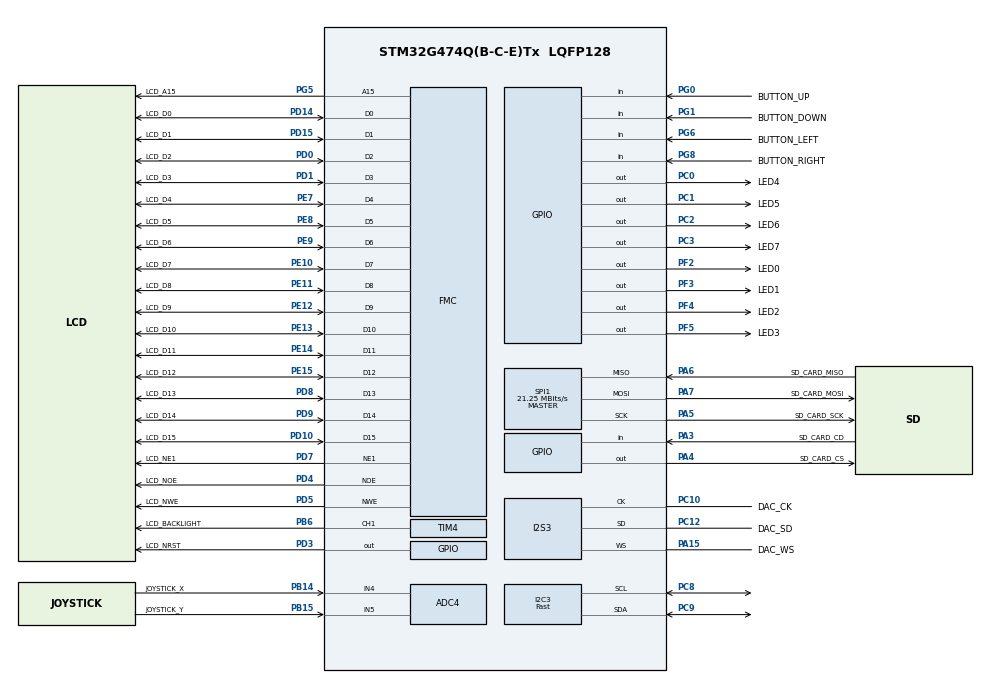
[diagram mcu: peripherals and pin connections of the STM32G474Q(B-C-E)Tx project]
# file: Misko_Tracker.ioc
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ADC4.Channel-0\#ChannelRegularConversion=ADC_CHANNEL_4
ADC4.Channel-1\#ChannelRegularConversion=ADC_CHANNEL_5
ADC4.DMAContinuousRequests=ENABLE
ADC4.ExternalTrigConv=ADC_EXTERNALTRIG_T3_TRGO
ADC4.NbrOfConversion=2
ADC4.NbrOfConversionFlag=1
ADC4.OffsetNumber-0\#ChannelRegularConversion=ADC_OFFSET_NONE
ADC4.OffsetNumber-1\#ChannelRegularConversion=ADC_OFFSET_NONE
ADC4.Rank-0\#ChannelRegularConversion=1
ADC4.Rank-1\#ChannelRegularConversion=2
ADC4.SamplingTime-0\#ChannelRegularConversion=ADC_SAMPLETIME_640CYCLES_5
ADC4.SamplingTime-1\#ChannelRegularConversion=ADC_SAMPLETIME_640CYCLES_5
Dma.ADC4.0.Direction=DMA_PERIPH_TO_MEMORY
Dma.ADC4.0.EventEnable=DISABLE
Dma.ADC4.0.Instance=DMA1_Channel2
Dma.ADC4.0.MemDataAlignment=DMA_MDATAALIGN_HALFWORD
Dma.ADC4.0.MemInc=DMA_MINC_ENABLE
Dma.ADC4.0.Mode=DMA_CIRCULAR
Dma.ADC4.0.PeriphDataAlignment=DMA_PDATAALIGN_HALFWORD
Dma.ADC4.0.PeriphInc=DMA_PINC_DISABLE
Dma.ADC4.0.Polarity=HAL_DMAMUX_REQ_GEN_RISING
Dma.ADC4.0.Priority=DMA_PRIORITY_LOW
Dma.ADC4.0.RequestNumber=1
Dma.ADC4.0.SignalID=NONE
Dma.ADC4.0.SyncEnable=DISABLE
Dma.ADC4.0.SyncPolarity=HAL_DMAMUX_SYNC_NO_EVENT
Dma.ADC4.0.SyncRequestNumber=1
Dma.ADC4.0.SyncSignalID=NONE
Dma.MEMTOMEM.1.Direction=DMA_MEMORY_TO_MEMORY
Dma.MEMTOMEM.1.EventEnable=DISABLE
Dma.MEMTOMEM.1.Instance=DMA1_Channel1
Dma.MEMTOMEM.1.MemDataAlignment=DMA_MDATAALIGN_HALFWORD
Dma.MEMTOMEM.1.MemInc=DMA_MINC_DISABLE
Dma.MEMTOMEM.1.Mode=DMA_NORMAL
Dma.MEMTOMEM.1.PeriphDataAlignment=DMA_PDATAALIGN_HALFWORD
Dma.MEMTOMEM.1.PeriphInc=DMA_PINC_ENABLE
Dma.MEMTOMEM.1.Polarity=HAL_DMAMUX_REQ_GEN_RISING
Dma.MEMTOMEM.1.Priority=DMA_PRIORITY_MEDIUM
Dma.MEMTOMEM.1.RequestNumber=1
Dma.MEMTOMEM.1.SignalID=NONE
Dma.MEMTOMEM.1.SyncEnable=DISABLE
Dma.MEMTOMEM.1.SyncPolarity=HAL_DMAMUX_SYNC_NO_EVENT
Dma.MEMTOMEM.1.SyncRequestNumber=1
Dma.MEMTOMEM.1.SyncSignalID=NONE
Dma.Request0=ADC4
Dma.Request1=MEMTOMEM
Dma.Request2=SPI3_TX
Dma.SPI3_TX.2.Direction=DMA_MEMORY_TO_PERIPH
Dma.SPI3_TX.2.EventEnable=DISABLE
Dma.SPI3_TX.2.Instance=DMA2_Channel1
Dma.SPI3_TX.2.MemDataAlignment=DMA_MDATAALIGN_HALFWORD
Dma.SPI3_TX.2.MemInc=DMA_MINC_ENABLE
Dma.SPI3_TX.2.Mode=DMA_CIRCULAR
Dma.SPI3_TX.2.PeriphDataAlignment=DMA_PDATAALIGN_HALFWORD
Dma.SPI3_TX.2.PeriphInc=DMA_PINC_DISABLE
Dma.SPI3_TX.2.Polarity=HAL_DMAMUX_REQ_GEN_RISING
Dma.SPI3_TX.2.Priority=DMA_PRIORITY_HIGH
Dma.SPI3_TX.2.RequestNumber=1
Dma.SPI3_TX.2.SignalID=NONE
Dma.SPI3_TX.2.SyncEnable=DISABLE
Dma.SPI3_TX.2.SyncPolarity=HAL_DMAMUX_SYNC_NO_EVENT
Dma.SPI3_TX.2.SyncRequestNumber=1
Dma.SPI3_TX.2.SyncSignalID=NONE
FMC.AddressSetupTime1=0
FMC.BusTurnAroundDuration1=0
FMC.DataHoldTime1=0
FMC.DataSetupTime1=1
I2C3.I2C_Speed_Mode=I2C_Fast
I2C3.Timing=0x40621236
I2S3.AudioFreq=I2S_AUDIOFREQ_48K
I2S3.ErrorAudioFreq=-0.29 %
I2S3.FullDuplexMode=I2S_FULLDUPLEXMODE_DISABLE
I2S3.Instance=SPI$Index
I2S3.RealAudioFreq=47.86 KHz
I2S3.VirtualMode=I2S_MODE_MASTER
Mcu.Family=STM32G4
Mcu.Name=STM32G474Q(B-C-E)Tx
Mcu.Package=LQFP128
NVIC.DMA1_Channel2_IRQn=true\:0\:0\:false\:false\:false\:false\:false\:false
NVIC.DMA2_Channel1_IRQn=true\:0\:0\:false\:false\:true\:false\:true\:true
NVIC.PriorityGroup=NVIC_PRIORITYGROUP_4
PA15.GPIO_Label=DAC_WS
PA15.Mode=Half_Duplex_Master
PA15.Signal=I2S3_WS
PA3.GPIO_Label=SD_CARD_CD
PA3.GPIO_PuPd=GPIO_NOPULL
PA3.Signal=GPIO_Input
PA4.GPIO_Label=SD_CARD_CS
PA4.GPIO_Speed=GPIO_SPEED_FREQ_LOW
PA4.Signal=GPIO_Output
PA5.GPIO_Label=SD_CARD_SCK
PA5.GPIO_Speed=GPIO_SPEED_FREQ_LOW
PA5.Mode=Full_Duplex_Master
PA5.Signal=SPI1_SCK
PA6.GPIO_Label=SD_CARD_MISO
PA6.GPIO_Speed=GPIO_SPEED_FREQ_LOW
PA6.Mode=Full_Duplex_Master
PA6.Signal=SPI1_MISO
PA7.GPIO_Label=SD_CARD_MOSI
PA7.GPIO_Speed=GPIO_SPEED_FREQ_LOW
PA7.Mode=Full_Duplex_Master
PA7.Signal=SPI1_MOSI
PB14.GPIO_Label=JOYSTICK_X
PB14.Mode=IN4-Single-Ended
PB14.Signal=ADC4_IN4
PB15.GPIO_Label=JOYSTICK_Y
PB15.Mode=IN5-Single-Ended
PB15.Signal=ADC4_IN5
PB6.GPIO_Label=LCD_BACKLIGHT
PB6.Signal=S_TIM4_CH1
PC0.GPIO_Label=LED4
PC0.Signal=GPIO_Output
PC1.GPIO_Label=LED5
PC1.Signal=GPIO_Output
PC10.GPIO_Label=DAC_CK
PC10.Mode=Half_Duplex_Master
PC10.Signal=I2S3_CK
PC12.GPIO_Label=DAC_SD
PC12.Mode=Half_Duplex_Master
PC12.Signal=I2S3_SD
PC2.GPIO_Label=LED6
PC2.Signal=GPIO_Output
PC3.GPIO_Label=LED7
PC3.Signal=GPIO_Output
PC8.Mode=I2C
PC8.Signal=I2C3_SCL
PC9.Mode=I2C
PC9.Signal=I2C3_SDA
PD0.GPIO_Label=LCD_D2
PD0.Signal=FMC_D2_DA2
PD1.GPIO_Label=LCD_D3
PD1.Signal=FMC_D3_DA3
PD10.GPIO_Label=LCD_D15
PD10.Signal=FMC_D15_DA15
PD14.GPIO_Label=LCD_D0
PD14.Signal=FMC_D0_DA0
PD15.GPIO_Label=LCD_D1
PD15.Signal=FMC_D1_DA1
PD3.GPIO_Label=LCD_NRST
PD3.Signal=GPIO_Output
PD4.GPIO_Label=LCD_NOE
PD4.Signal=FMC_NOE
PD5.GPIO_Label=LCD_NWE
PD5.Signal=FMC_NWE
PD7.GPIO_Label=LCD_NE1
PD7.Mode=NorPsramChipSelect1_1
PD7.Signal=FMC_NE1
PD8.GPIO_Label=LCD_D13
PD8.Signal=FMC_D13_DA13
PD9.GPIO_Label=LCD_D14
PD9.Signal=FMC_D14_DA14
PE10.GPIO_Label=LCD_D7
PE10.Signal=FMC_D7_DA7
PE11.GPIO_Label=LCD_D8
PE11.Signal=FMC_D8_DA8
PE12.GPIO_Label=LCD_D9
PE12.Signal=FMC_D9_DA9
PE13.GPIO_Label=LCD_D10
PE13.Signal=FMC_D10_DA10
PE14.GPIO_Label=LCD_D11
PE14.Signal=FMC_D11_DA11
PE15.GPIO_Label=LCD_D12
PE15.Signal=FMC_D12_DA12
PE7.GPIO_Label=LCD_D4
PE7.Signal=FMC_D4_DA4
PE8.GPIO_Label=LCD_D5
PE8.Signal=FMC_D5_DA5
PE9.GPIO_Label=LCD_D6
PE9.Signal=FMC_D6_DA6
PF0-OSC_IN.GPIO_Label=EXTERNAL_CLOCK
PF0-OSC_IN.Mode=HSE-External-Clock-Source
PF0-OSC_IN.Signal=RCC_OSC_IN
PF2.GPIO_Label=LED0
PF2.Signal=GPIO_Output
PF3.GPIO_Label=LED1
PF3.Signal=GPIO_Output
PF4.GPIO_Label=LED2
PF4.Signal=GPIO_Output
PF5.GPIO_Label=LED3
PF5.Signal=GPIO_Output
PG0.GPIO_Label=BUTTON_UP
PG0.GPIO_PuPd=GPIO_PULLUP
PG0.Signal=GPIO_Input
PG1.GPIO_Label=BUTTON_DOWN
PG1.GPIO_PuPd=GPIO_PULLUP
PG1.Signal=GPIO_Input
PG5.GPIO_Label=LCD_A15
PG5.Signal=FMC_A15
PG6.GPIO_Label=BUTTON_LEFT
PG6.GPIO_PuPd=GPIO_PULLUP
PG6.Signal=GPIO_Input
PG8.GPIO_Label=BUTTON_RIGHT
PG8.GPIO_PuPd=GPIO_PULLUP
PG8.Signal=GPIO_Input
ProjectManager.HeapSize=0x200
ProjectManager.StackSize=0x400
ProjectManager.TargetToolchain=STM32CubeIDE
RCC.ADC12Freq_Value=170000000
RCC.ADC345Freq_Value=170000000
RCC.AHBFreq_Value=170000000
RCC.APB1Freq_Value=170000000
RCC.APB1TimFreq_Value=170000000
RCC.APB2Freq_Value=170000000
RCC.APB2TimFreq_Value=170000000
RCC.CK48CLockSelection=RCC_USBCLKSOURCE_HSI48
RCC.CortexFreq_Value=170000000
RCC.EXTERNAL_CLOCK_VALUE=12288000
RCC.HCLKFreq_Value=170000000
RCC.HSE_VALUE=8000000
RCC.HSI48_VALUE=48000000
RCC.HSI_VALUE=16000000
RCC.LSE_VALUE=32768
RCC.PLLM=RCC_PLLM_DIV2
RCC.PLLN=85
RCC.PLLSourceVirtual=RCC_PLLSOURCE_HSE
RCC.SYSCLKFreq_VALUE=170000000
RCC.SYSCLKSource=RCC_SYSCLKSOURCE_PLLCLK
RCC.USBFreq_Value=48000000
RCC.VCOOutputFreq_Value=340000000
SH.FMC_A15.0=FMC_A15,A15_1
SH.FMC_D0_DA0.0=FMC_D0,16b-d1
SH.FMC_D10_DA10.0=FMC_D10,16b-d1
SH.FMC_D11_DA11.0=FMC_D11,16b-d1
SH.FMC_D12_DA12.0=FMC_D12,16b-d1
SH.FMC_D13_DA13.0=FMC_D13,16b-d1
SH.FMC_D14_DA14.0=FMC_D14,16b-d1
SH.FMC_D15_DA15.0=FMC_D15,16b-d1
SH.FMC_D1_DA1.0=FMC_D1,16b-d1
SH.FMC_D2_DA2.0=FMC_D2,16b-d1
SH.FMC_D3_DA3.0=FMC_D3,16b-d1
SH.FMC_D4_DA4.0=FMC_D4,16b-d1
SH.FMC_D5_DA5.0=FMC_D5,16b-d1
SH.FMC_D6_DA6.0=FMC_D6,16b-d1
SH.FMC_D7_DA7.0=FMC_D7,16b-d1
SH.FMC_D8_DA8.0=FMC_D8,16b-d1
SH.FMC_D9_DA9.0=FMC_D9,16b-d1
SH.FMC_NOE.0=FMC_NOE,Lcd1
SH.FMC_NWE.0=FMC_NWE,Lcd1
SH.S_TIM4_CH1.0=TIM4_CH1,PWM Generation1 CH1
SPI1.BaudRatePrescaler=SPI_BAUDRATEPRESCALER_8
SPI1.CLKPhase=SPI_PHASE_1EDGE
SPI1.CLKPolarity=SPI_POLARITY_LOW
SPI1.CalculateBaudRate=21.25 MBits/s
SPI1.DataSize=SPI_DATASIZE_8BIT
SPI1.Direction=SPI_DIRECTION_2LINES
SPI1.FirstBit=SPI_FIRSTBIT_MSB
SPI1.Mode=SPI_MODE_MASTER
SPI1.NSSPMode=SPI_NSS_PULSE_ENABLE
SPI1.VirtualType=VM_MASTER
TIM2.PeriodNoDither=4294967295
TIM2.Prescaler=169
TIM3.PeriodNoDither=9999
TIM3.Prescaler=169
TIM3.TIM_MasterOutputTrigger=TIM_TRGO_UPDATE
TIM4.Channel-PWM\ Generation1\ CH1=TIM_CHANNEL_1
TIM4.PeriodNoDither=99
TIM4.Prescaler=69
VP_CORDIC_VS_CORDIC.Mode=CORDIC_Activate
VP_SYS_VS_DBSignals.Mode=DisableDeadBatterySignals
VP_TIM2_VS_ClockSourceINT.Mode=Internal
VP_TIM3_VS_ClockSourceINT.Mode=Internal
VP_TIM4_VS_ClockSourceINT.Mode=Internal
board=custom

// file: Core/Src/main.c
/* USER CODE BEGIN Header */
/**
  ******************************************************************************
  * @file           : main.c
  * @brief          : Main program body
  ******************************************************************************
  * @attention
  *
  * Copyright (c) 2024 STMicroelectronics.
  * All rights reserved.
  *
  * This software is licensed under terms that can be found in the LICENSE file
  * in the root directory of this software component.
  * If no LICENSE file comes with this software, it is provided AS-IS.
  *
  ******************************************************************************
  */
/* USER CODE END Header */
#include "main.h"

/* USER CODE BEGIN Includes */
#include "app.h"
/* USER CODE END Includes */

SRAM_HandleTypeDef hsram1;

void SystemClock_Config(void);
static void MX_GPIO_Init(void);
static void MX_DMA_Init(void);
static void MX_TIM2_Init(void);
static void MX_ADC4_Init(void);
static void MX_TIM3_Init(void);
static void MX_TIM4_Init(void);
static void MX_FMC_Init(void);
static void MX_SPI1_Init(void);
static void MX_CORDIC_Init(void);
static void MX_I2S3_Init(void);
static void MX_I2C3_Init(void);

int main(void)
{

  /* MCU Configuration--------------------------------------------------------*/

  /* Reset of all peripherals, Initializes the Flash interface and the Systick. */
  HAL_Init();

  /* Configure the system clock */
  SystemClock_Config();

  /* Initialize all configured peripherals */
  MX_GPIO_Init();
  MX_DMA_Init();
  MX_TIM2_Init();
  MX_ADC4_Init();
  MX_TIM3_Init();
  MX_TIM4_Init();
  MX_FMC_Init();
  MX_SPI1_Init();
  MX_CORDIC_Init();
  MX_I2S3_Init();
  MX_I2C3_Init();
  /* USER CODE BEGIN 2 */
  // Disable SysTick.
  SysTick->CTRL = 0;

  // Run main application.
  app();
  /* USER CODE END 2 */

  /* Infinite loop */
  while (1)
  {

  }
}

void SystemClock_Config(void)
{
  LL_FLASH_SetLatency(LL_FLASH_LATENCY_4);
  while(LL_FLASH_GetLatency() != LL_FLASH_LATENCY_4)
  {
  }
  LL_PWR_EnableRange1BoostMode();
  LL_RCC_HSE_EnableBypass();
  LL_RCC_HSE_Enable();
   /* Wait till HSE is ready */
  while(LL_RCC_HSE_IsReady() != 1)
  {
  }

  LL_RCC_PLL_ConfigDomain_SYS(LL_RCC_PLLSOURCE_HSE, LL_RCC_PLLM_DIV_2, 85, LL_RCC_PLLR_DIV_2);
  LL_RCC_PLL_EnableDomain_SYS();
  LL_RCC_PLL_Enable();
   /* Wait till PLL is ready */
  while(LL_RCC_PLL_IsReady() != 1)
  {
  }

  LL_RCC_SetSysClkSource(LL_RCC_SYS_CLKSOURCE_PLL);
  LL_RCC_SetAHBPrescaler(LL_RCC_SYSCLK_DIV_2);
   /* Wait till System clock is ready */
  while(LL_RCC_GetSysClkSource() != LL_RCC_SYS_CLKSOURCE_STATUS_PLL)
  {
  }

  /* Insure 1us transition state at intermediate medium speed clock*/
  for (__IO uint32_t i = (170 >> 1); i !=0; i--);

  /* Set AHB prescaler*/
  LL_RCC_SetAHBPrescaler(LL_RCC_SYSCLK_DIV_1);
  LL_RCC_SetAPB1Prescaler(LL_RCC_APB1_DIV_1);
  LL_RCC_SetAPB2Prescaler(LL_RCC_APB2_DIV_1);
  LL_SetSystemCoreClock(170000000);

   /* Update the time base */
  if (HAL_InitTick (TICK_INT_PRIORITY) != HAL_OK)
  {
    Error_Handler();
  }
}

static void MX_ADC4_Init(void)
{

  LL_ADC_InitTypeDef ADC_InitStruct = {0};
  LL_ADC_REG_InitTypeDef ADC_REG_InitStruct = {0};
  LL_ADC_CommonInitTypeDef ADC_CommonInitStruct = {0};

  LL_GPIO_InitTypeDef GPIO_InitStruct = {0};

  LL_RCC_SetADCClockSource(LL_RCC_ADC345_CLKSOURCE_SYSCLK);

  /* Peripheral clock enable */
  LL_AHB2_GRP1_EnableClock(LL_AHB2_GRP1_PERIPH_ADC345);

  LL_AHB2_GRP1_EnableClock(LL_AHB2_GRP1_PERIPH_GPIOB);
  /**ADC4 GPIO Configuration
  PB14   ------> ADC4_IN4
  PB15   ------> ADC4_IN5
  */
  GPIO_InitStruct.Pin = JOYSTICK_X_Pin;
  GPIO_InitStruct.Mode = LL_GPIO_MODE_ANALOG;
  GPIO_InitStruct.Pull = LL_GPIO_PULL_NO;
  LL_GPIO_Init(JOYSTICK_X_GPIO_Port, &GPIO_InitStruct);

  GPIO_InitStruct.Pin = JOYSTICK_Y_Pin;
  GPIO_InitStruct.Mode = LL_GPIO_MODE_ANALOG;
  GPIO_InitStruct.Pull = LL_GPIO_PULL_NO;
  LL_GPIO_Init(JOYSTICK_Y_GPIO_Port, &GPIO_InitStruct);

  /* ADC4 DMA Init */

  /* ADC4 Init */
  LL_DMA_SetPeriphRequest(DMA1, LL_DMA_CHANNEL_2, LL_DMAMUX_REQ_ADC4);

  LL_DMA_SetDataTransferDirection(DMA1, LL_DMA_CHANNEL_2, LL_DMA_DIRECTION_PERIPH_TO_MEMORY);

  LL_DMA_SetChannelPriorityLevel(DMA1, LL_DMA_CHANNEL_2, LL_DMA_PRIORITY_LOW);

  LL_DMA_SetMode(DMA1, LL_DMA_CHANNEL_2, LL_DMA_MODE_CIRCULAR);

  LL_DMA_SetPeriphIncMode(DMA1, LL_DMA_CHANNEL_2, LL_DMA_PERIPH_NOINCREMENT);

  LL_DMA_SetMemoryIncMode(DMA1, LL_DMA_CHANNEL_2, LL_DMA_MEMORY_INCREMENT);

  LL_DMA_SetPeriphSize(DMA1, LL_DMA_CHANNEL_2, LL_DMA_PDATAALIGN_HALFWORD);

  LL_DMA_SetMemorySize(DMA1, LL_DMA_CHANNEL_2, LL_DMA_MDATAALIGN_HALFWORD);

  /** Common config
  */
  ADC_InitStruct.Resolution = LL_ADC_RESOLUTION_12B;
  ADC_InitStruct.DataAlignment = LL_ADC_DATA_ALIGN_RIGHT;
  ADC_InitStruct.LowPowerMode = LL_ADC_LP_MODE_NONE;
  LL_ADC_Init(ADC4, &ADC_InitStruct);
  ADC_REG_InitStruct.TriggerSource = LL_ADC_REG_TRIG_EXT_TIM3_TRGO;
  ADC_REG_InitStruct.SequencerLength = LL_ADC_REG_SEQ_SCAN_ENABLE_2RANKS;
  ADC_REG_InitStruct.SequencerDiscont = LL_ADC_REG_SEQ_DISCONT_DISABLE;
  ADC_REG_InitStruct.ContinuousMode = LL_ADC_REG_CONV_SINGLE;
  ADC_REG_InitStruct.DMATransfer = LL_ADC_REG_DMA_TRANSFER_UNLIMITED;
  ADC_REG_InitStruct.Overrun = LL_ADC_REG_OVR_DATA_PRESERVED;
  LL_ADC_REG_Init(ADC4, &ADC_REG_InitStruct);
  LL_ADC_SetGainCompensation(ADC4, 0);
  LL_ADC_SetOverSamplingScope(ADC4, LL_ADC_OVS_DISABLE);
  ADC_CommonInitStruct.CommonClock = LL_ADC_CLOCK_SYNC_PCLK_DIV4;
  LL_ADC_CommonInit(__LL_ADC_COMMON_INSTANCE(ADC4), &ADC_CommonInitStruct);
  LL_ADC_REG_SetTriggerEdge(ADC4, LL_ADC_REG_TRIG_EXT_RISING);

  /* Disable ADC deep power down (enabled by default after reset state) */
  LL_ADC_DisableDeepPowerDown(ADC4);
  /* Enable ADC internal voltage regulator */
  LL_ADC_EnableInternalRegulator(ADC4);
  /* Delay for ADC internal voltage regulator stabilization. */
  /* Compute number of CPU cycles to wait for, from delay in us. */
  /* Note: Variable divided by 2 to compensate partially */
  /* CPU processing cycles (depends on compilation optimization). */
  /* Note: If system core clock frequency is below 200kHz, wait time */
  /* is only a few CPU processing cycles. */
  uint32_t wait_loop_index;
  wait_loop_index = ((LL_ADC_DELAY_INTERNAL_REGUL_STAB_US * (SystemCoreClock / (100000 * 2))) / 10);
  while(wait_loop_index != 0)
  {
    wait_loop_index--;
  }

  /** Configure Regular Channel
  */
  LL_ADC_REG_SetSequencerRanks(ADC4, LL_ADC_REG_RANK_1, LL_ADC_CHANNEL_4);
  LL_ADC_SetChannelSamplingTime(ADC4, LL_ADC_CHANNEL_4, LL_ADC_SAMPLINGTIME_640CYCLES_5);
  LL_ADC_SetChannelSingleDiff(ADC4, LL_ADC_CHANNEL_4, LL_ADC_SINGLE_ENDED);

  /** Configure Regular Channel
  */
  LL_ADC_REG_SetSequencerRanks(ADC4, LL_ADC_REG_RANK_2, LL_ADC_CHANNEL_5);
  LL_ADC_SetChannelSamplingTime(ADC4, LL_ADC_CHANNEL_5, LL_ADC_SAMPLINGTIME_640CYCLES_5);
  LL_ADC_SetChannelSingleDiff(ADC4, LL_ADC_CHANNEL_5, LL_ADC_SINGLE_ENDED);

}

static void MX_CORDIC_Init(void)
{

  /* Peripheral clock enable */
  LL_AHB1_GRP1_EnableClock(LL_AHB1_GRP1_PERIPH_CORDIC);

  /* nothing else to be configured */

}

static void MX_I2C3_Init(void)
{

  LL_I2C_InitTypeDef I2C_InitStruct = {0};

  LL_GPIO_InitTypeDef GPIO_InitStruct = {0};

  LL_RCC_SetI2CClockSource(LL_RCC_I2C3_CLKSOURCE_PCLK1);

  LL_AHB2_GRP1_EnableClock(LL_AHB2_GRP1_PERIPH_GPIOC);
  /**I2C3 GPIO Configuration
  PC8   ------> I2C3_SCL
  PC9   ------> I2C3_SDA
  */
  GPIO_InitStruct.Pin = LL_GPIO_PIN_8;
  GPIO_InitStruct.Mode = LL_GPIO_MODE_ALTERNATE;
  GPIO_InitStruct.Speed = LL_GPIO_SPEED_FREQ_LOW;
  GPIO_InitStruct.OutputType = LL_GPIO_OUTPUT_OPENDRAIN;
  GPIO_InitStruct.Pull = LL_GPIO_PULL_NO;
  GPIO_InitStruct.Alternate = LL_GPIO_AF_8;
  LL_GPIO_Init(GPIOC, &GPIO_InitStruct);

  GPIO_InitStruct.Pin = LL_GPIO_PIN_9;
  GPIO_InitStruct.Mode = LL_GPIO_MODE_ALTERNATE;
  GPIO_InitStruct.Speed = LL_GPIO_SPEED_FREQ_LOW;
  GPIO_InitStruct.OutputType = LL_GPIO_OUTPUT_OPENDRAIN;
  GPIO_InitStruct.Pull = LL_GPIO_PULL_NO;
  GPIO_InitStruct.Alternate = LL_GPIO_AF_8;
  LL_GPIO_Init(GPIOC, &GPIO_InitStruct);

  /* Peripheral clock enable */
  LL_APB1_GRP1_EnableClock(LL_APB1_GRP1_PERIPH_I2C3);

  /** I2C Initialization
  */
  I2C_InitStruct.PeripheralMode = LL_I2C_MODE_I2C;
  I2C_InitStruct.Timing = 0x40621236;
  I2C_InitStruct.AnalogFilter = LL_I2C_ANALOGFILTER_ENABLE;
  I2C_InitStruct.DigitalFilter = 0;
  I2C_InitStruct.OwnAddress1 = 0;
  I2C_InitStruct.TypeAcknowledge = LL_I2C_ACK;
  I2C_InitStruct.OwnAddrSize = LL_I2C_OWNADDRESS1_7BIT;
  LL_I2C_Init(I2C3, &I2C_InitStruct);
  LL_I2C_EnableAutoEndMode(I2C3);
  LL_I2C_SetOwnAddress2(I2C3, 0, LL_I2C_OWNADDRESS2_NOMASK);
  LL_I2C_DisableOwnAddress2(I2C3);
  LL_I2C_DisableGeneralCall(I2C3);
  LL_I2C_EnableClockStretching(I2C3);
  /* USER CODE BEGIN I2C3_Init 2 */
  LL_DMA_SetPeriphAddress(DMA2, LL_DMA_CHANNEL_1, (uint32_t)&SPI3->DR);
  //LL_I2C_Enable(I2C3);
  /* USER CODE END I2C3_Init 2 */

}

static void MX_I2S3_Init(void)
{

  LL_I2S_InitTypeDef I2S_InitStruct = {0};

  LL_GPIO_InitTypeDef GPIO_InitStruct = {0};

  LL_RCC_SetI2SClockSource(LL_RCC_I2S_CLKSOURCE_SYSCLK);

  /* Peripheral clock enable */
  LL_APB1_GRP1_EnableClock(LL_APB1_GRP1_PERIPH_SPI3);

  LL_AHB2_GRP1_EnableClock(LL_AHB2_GRP1_PERIPH_GPIOA);
  LL_AHB2_GRP1_EnableClock(LL_AHB2_GRP1_PERIPH_GPIOC);
  /**I2S3 GPIO Configuration
  PA15   ------> I2S3_WS
  PC10   ------> I2S3_CK
  PC12   ------> I2S3_SD
  */
  GPIO_InitStruct.Pin = DAC_WS_Pin;
  GPIO_InitStruct.Mode = LL_GPIO_MODE_ALTERNATE;
  GPIO_InitStruct.Speed = LL_GPIO_SPEED_FREQ_LOW;
  GPIO_InitStruct.OutputType = LL_GPIO_OUTPUT_PUSHPULL;
  GPIO_InitStruct.Pull = LL_GPIO_PULL_NO;
  GPIO_InitStruct.Alternate = LL_GPIO_AF_6;
  LL_GPIO_Init(DAC_WS_GPIO_Port, &GPIO_InitStruct);

  GPIO_InitStruct.Pin = DAC_CK_Pin;
  GPIO_InitStruct.Mode = LL_GPIO_MODE_ALTERNATE;
  GPIO_InitStruct.Speed = LL_GPIO_SPEED_FREQ_LOW;
  GPIO_InitStruct.OutputType = LL_GPIO_OUTPUT_PUSHPULL;
  GPIO_InitStruct.Pull = LL_GPIO_PULL_NO;
  GPIO_InitStruct.Alternate = LL_GPIO_AF_6;
  LL_GPIO_Init(DAC_CK_GPIO_Port, &GPIO_InitStruct);

  GPIO_InitStruct.Pin = DAC_SD_Pin;
  GPIO_InitStruct.Mode = LL_GPIO_MODE_ALTERNATE;
  GPIO_InitStruct.Speed = LL_GPIO_SPEED_FREQ_LOW;
  GPIO_InitStruct.OutputType = LL_GPIO_OUTPUT_PUSHPULL;
  GPIO_InitStruct.Pull = LL_GPIO_PULL_NO;
  GPIO_InitStruct.Alternate = LL_GPIO_AF_6;
  LL_GPIO_Init(DAC_SD_GPIO_Port, &GPIO_InitStruct);

  /* I2S3 DMA Init */

  /* SPI3_TX Init */
  LL_DMA_SetPeriphRequest(DMA2, LL_DMA_CHANNEL_1, LL_DMAMUX_REQ_SPI3_TX);

  LL_DMA_SetDataTransferDirection(DMA2, LL_DMA_CHANNEL_1, LL_DMA_DIRECTION_MEMORY_TO_PERIPH);

  LL_DMA_SetChannelPriorityLevel(DMA2, LL_DMA_CHANNEL_1, LL_DMA_PRIORITY_HIGH);

  LL_DMA_SetMode(DMA2, LL_DMA_CHANNEL_1, LL_DMA_MODE_CIRCULAR);

  LL_DMA_SetPeriphIncMode(DMA2, LL_DMA_CHANNEL_1, LL_DMA_PERIPH_NOINCREMENT);

  LL_DMA_SetMemoryIncMode(DMA2, LL_DMA_CHANNEL_1, LL_DMA_MEMORY_INCREMENT);

  LL_DMA_SetPeriphSize(DMA2, LL_DMA_CHANNEL_1, LL_DMA_PDATAALIGN_HALFWORD);

  LL_DMA_SetMemorySize(DMA2, LL_DMA_CHANNEL_1, LL_DMA_MDATAALIGN_HALFWORD);

  I2S_InitStruct.Mode = LL_I2S_MODE_MASTER_TX;
  I2S_InitStruct.Standard = LL_I2S_STANDARD_PHILIPS;
  I2S_InitStruct.DataFormat = LL_I2S_DATAFORMAT_16B;
  I2S_InitStruct.MCLKOutput = LL_I2S_MCLK_OUTPUT_DISABLE;
  I2S_InitStruct.AudioFreq = LL_I2S_AUDIOFREQ_48K;
  I2S_InitStruct.ClockPolarity = LL_I2S_POLARITY_LOW;
  LL_I2S_Init(SPI3, &I2S_InitStruct);
  /* USER CODE BEGIN I2S3_Init 2 */
  LL_DMA_EnableIT_HT(DMA2, LL_DMA_CHANNEL_1);
  LL_DMA_EnableIT_TC(DMA2, LL_DMA_CHANNEL_1);
  /* USER CODE END I2S3_Init 2 */

}

static void MX_SPI1_Init(void)
{

  LL_SPI_InitTypeDef SPI_InitStruct = {0};

  LL_GPIO_InitTypeDef GPIO_InitStruct = {0};

  /* Peripheral clock enable */
  LL_APB2_GRP1_EnableClock(LL_APB2_GRP1_PERIPH_SPI1);

  LL_AHB2_GRP1_EnableClock(LL_AHB2_GRP1_PERIPH_GPIOA);
  /**SPI1 GPIO Configuration
  PA5   ------> SPI1_SCK
  PA6   ------> SPI1_MISO
  PA7   ------> SPI1_MOSI
  */
  GPIO_InitStruct.Pin = SD_CARD_SCK_Pin;
  GPIO_InitStruct.Mode = LL_GPIO_MODE_ALTERNATE;
  GPIO_InitStruct.Speed = LL_GPIO_SPEED_FREQ_LOW;
  GPIO_InitStruct.OutputType = LL_GPIO_OUTPUT_PUSHPULL;
  GPIO_InitStruct.Pull = LL_GPIO_PULL_NO;
  GPIO_InitStruct.Alternate = LL_GPIO_AF_5;
  LL_GPIO_Init(SD_CARD_SCK_GPIO_Port, &GPIO_InitStruct);

  GPIO_InitStruct.Pin = SD_CARD_MISO_Pin;
  GPIO_InitStruct.Mode = LL_GPIO_MODE_ALTERNATE;
  GPIO_InitStruct.Speed = LL_GPIO_SPEED_FREQ_LOW;
  GPIO_InitStruct.OutputType = LL_GPIO_OUTPUT_PUSHPULL;
  GPIO_InitStruct.Pull = LL_GPIO_PULL_NO;
  GPIO_InitStruct.Alternate = LL_GPIO_AF_5;
  LL_GPIO_Init(SD_CARD_MISO_GPIO_Port, &GPIO_InitStruct);

  GPIO_InitStruct.Pin = SD_CARD_MOSI_Pin;
  GPIO_InitStruct.Mode = LL_GPIO_MODE_ALTERNATE;
  GPIO_InitStruct.Speed = LL_GPIO_SPEED_FREQ_LOW;
  GPIO_InitStruct.OutputType = LL_GPIO_OUTPUT_PUSHPULL;
  GPIO_InitStruct.Pull = LL_GPIO_PULL_NO;
  GPIO_InitStruct.Alternate = LL_GPIO_AF_5;
  LL_GPIO_Init(SD_CARD_MOSI_GPIO_Port, &GPIO_InitStruct);

  /* SPI1 parameter configuration*/
  SPI_InitStruct.TransferDirection = LL_SPI_FULL_DUPLEX;
  SPI_InitStruct.Mode = LL_SPI_MODE_MASTER;
  SPI_InitStruct.DataWidth = LL_SPI_DATAWIDTH_8BIT;
  SPI_InitStruct.ClockPolarity = LL_SPI_POLARITY_LOW;
  SPI_InitStruct.ClockPhase = LL_SPI_PHASE_1EDGE;
  SPI_InitStruct.NSS = LL_SPI_NSS_SOFT;
  SPI_InitStruct.BaudRate = LL_SPI_BAUDRATEPRESCALER_DIV8;
  SPI_InitStruct.BitOrder = LL_SPI_MSB_FIRST;
  SPI_InitStruct.CRCCalculation = LL_SPI_CRCCALCULATION_DISABLE;
  SPI_InitStruct.CRCPoly = 7;
  LL_SPI_Init(SPI1, &SPI_InitStruct);
  LL_SPI_SetStandard(SPI1, LL_SPI_PROTOCOL_MOTOROLA);
  LL_SPI_EnableNSSPulseMgt(SPI1);
  /* USER CODE BEGIN SPI1_Init 2 */
  LL_SPI_Enable(SPI1);
  /* USER CODE END SPI1_Init 2 */

}

static void MX_TIM2_Init(void)
{

  LL_TIM_InitTypeDef TIM_InitStruct = {0};

  /* Peripheral clock enable */
  LL_APB1_GRP1_EnableClock(LL_APB1_GRP1_PERIPH_TIM2);

  TIM_InitStruct.Prescaler = 169;
  TIM_InitStruct.CounterMode = LL_TIM_COUNTERMODE_UP;
  TIM_InitStruct.Autoreload = 4294967295;
  TIM_InitStruct.ClockDivision = LL_TIM_CLOCKDIVISION_DIV1;
  LL_TIM_Init(TIM2, &TIM_InitStruct);
  LL_TIM_DisableARRPreload(TIM2);
  LL_TIM_SetClockSource(TIM2, LL_TIM_CLOCKSOURCE_INTERNAL);
  LL_TIM_SetTriggerOutput(TIM2, LL_TIM_TRGO_RESET);
  LL_TIM_DisableMasterSlaveMode(TIM2);

}

static void MX_TIM3_Init(void)
{

  LL_TIM_InitTypeDef TIM_InitStruct = {0};

  /* Peripheral clock enable */
  LL_APB1_GRP1_EnableClock(LL_APB1_GRP1_PERIPH_TIM3);

  TIM_InitStruct.Prescaler = 169;
  TIM_InitStruct.CounterMode = LL_TIM_COUNTERMODE_UP;
  TIM_InitStruct.Autoreload = 9999;
  TIM_InitStruct.ClockDivision = LL_TIM_CLOCKDIVISION_DIV1;
  LL_TIM_Init(TIM3, &TIM_InitStruct);
  LL_TIM_DisableARRPreload(TIM3);
  LL_TIM_SetClockSource(TIM3, LL_TIM_CLOCKSOURCE_INTERNAL);
  LL_TIM_SetTriggerOutput(TIM3, LL_TIM_TRGO_UPDATE);
  LL_TIM_DisableMasterSlaveMode(TIM3);

}

static void MX_TIM4_Init(void)
{

  LL_TIM_InitTypeDef TIM_InitStruct = {0};
  LL_TIM_OC_InitTypeDef TIM_OC_InitStruct = {0};

  LL_GPIO_InitTypeDef GPIO_InitStruct = {0};

  /* Peripheral clock enable */
  LL_APB1_GRP1_EnableClock(LL_APB1_GRP1_PERIPH_TIM4);

  TIM_InitStruct.Prescaler = 69;
  TIM_InitStruct.CounterMode = LL_TIM_COUNTERMODE_UP;
  TIM_InitStruct.Autoreload = 99;
  TIM_InitStruct.ClockDivision = LL_TIM_CLOCKDIVISION_DIV1;
  LL_TIM_Init(TIM4, &TIM_InitStruct);
  LL_TIM_DisableARRPreload(TIM4);
  LL_TIM_SetClockSource(TIM4, LL_TIM_CLOCKSOURCE_INTERNAL);
  LL_TIM_OC_EnablePreload(TIM4, LL_TIM_CHANNEL_CH1);
  TIM_OC_InitStruct.OCMode = LL_TIM_OCMODE_PWM1;
  TIM_OC_InitStruct.OCState = LL_TIM_OCSTATE_DISABLE;
  TIM_OC_InitStruct.OCNState = LL_TIM_OCSTATE_DISABLE;
  TIM_OC_InitStruct.CompareValue = 0;
  TIM_OC_InitStruct.OCPolarity = LL_TIM_OCPOLARITY_HIGH;
  LL_TIM_OC_Init(TIM4, LL_TIM_CHANNEL_CH1, &TIM_OC_InitStruct);
  LL_TIM_OC_DisableFast(TIM4, LL_TIM_CHANNEL_CH1);
  LL_TIM_SetTriggerOutput(TIM4, LL_TIM_TRGO_RESET);
  LL_TIM_DisableMasterSlaveMode(TIM4);
  LL_AHB2_GRP1_EnableClock(LL_AHB2_GRP1_PERIPH_GPIOB);
  /**TIM4 GPIO Configuration
  PB6   ------> TIM4_CH1
  */
  GPIO_InitStruct.Pin = LCD_BACKLIGHT_Pin;
  GPIO_InitStruct.Mode = LL_GPIO_MODE_ALTERNATE;
  GPIO_InitStruct.Speed = LL_GPIO_SPEED_FREQ_LOW;
  GPIO_InitStruct.OutputType = LL_GPIO_OUTPUT_PUSHPULL;
  GPIO_InitStruct.Pull = LL_GPIO_PULL_NO;
  GPIO_InitStruct.Alternate = LL_GPIO_AF_2;
  LL_GPIO_Init(LCD_BACKLIGHT_GPIO_Port, &GPIO_InitStruct);

}

static void MX_DMA_Init(void)
{

  /* Init with LL driver */
  /* DMA controller clock enable */
  LL_AHB1_GRP1_EnableClock(LL_AHB1_GRP1_PERIPH_DMAMUX1);
  LL_AHB1_GRP1_EnableClock(LL_AHB1_GRP1_PERIPH_DMA1);
  LL_AHB1_GRP1_EnableClock(LL_AHB1_GRP1_PERIPH_DMA2);

  /* Configure DMA request MEMTOMEM_DMA1_Channel1 */

  /* Set request number */
  LL_DMA_SetPeriphRequest(DMA1, LL_DMA_CHANNEL_1, LL_DMAMUX_REQ_MEM2MEM);

  /* Set transfer direction */
  LL_DMA_SetDataTransferDirection(DMA1, LL_DMA_CHANNEL_1, LL_DMA_DIRECTION_MEMORY_TO_MEMORY);

  /* Set priority level */
  LL_DMA_SetChannelPriorityLevel(DMA1, LL_DMA_CHANNEL_1, LL_DMA_PRIORITY_MEDIUM);

  /* Set DMA mode */
  LL_DMA_SetMode(DMA1, LL_DMA_CHANNEL_1, LL_DMA_MODE_NORMAL);

  /* Set peripheral increment mode */
  LL_DMA_SetPeriphIncMode(DMA1, LL_DMA_CHANNEL_1, LL_DMA_PERIPH_INCREMENT);

  /* Set memory increment mode */
  LL_DMA_SetMemoryIncMode(DMA1, LL_DMA_CHANNEL_1, LL_DMA_MEMORY_NOINCREMENT);

  /* Set peripheral data width */
  LL_DMA_SetPeriphSize(DMA1, LL_DMA_CHANNEL_1, LL_DMA_PDATAALIGN_HALFWORD);

  /* Set memory data width */
  LL_DMA_SetMemorySize(DMA1, LL_DMA_CHANNEL_1, LL_DMA_MDATAALIGN_HALFWORD);

  /* DMA interrupt init */
  /* DMA1_Channel2_IRQn interrupt configuration */
  NVIC_SetPriority(DMA1_Channel2_IRQn, NVIC_EncodePriority(NVIC_GetPriorityGrouping(),0, 0));
  NVIC_EnableIRQ(DMA1_Channel2_IRQn);
  /* DMA2_Channel1_IRQn interrupt configuration */
  NVIC_SetPriority(DMA2_Channel1_IRQn, NVIC_EncodePriority(NVIC_GetPriorityGrouping(),0, 0));
  NVIC_EnableIRQ(DMA2_Channel1_IRQn);

}

/* FMC initialization function */
static void MX_FMC_Init(void)
{

  FMC_NORSRAM_TimingTypeDef Timing = {0};

  /** Perform the SRAM1 memory initialization sequence
  */
  hsram1.Instance = FMC_NORSRAM_DEVICE;
  hsram1.Extended = FMC_NORSRAM_EXTENDED_DEVICE;
  /* hsram1.Init */
  hsram1.Init.NSBank = FMC_NORSRAM_BANK1;
  hsram1.Init.DataAddressMux = FMC_DATA_ADDRESS_MUX_DISABLE;
  hsram1.Init.MemoryType = FMC_MEMORY_TYPE_SRAM;
  hsram1.Init.MemoryDataWidth = FMC_NORSRAM_MEM_BUS_WIDTH_16;
  hsram1.Init.BurstAccessMode = FMC_BURST_ACCESS_MODE_DISABLE;
  hsram1.Init.WaitSignalPolarity = FMC_WAIT_SIGNAL_POLARITY_LOW;
  hsram1.Init.WaitSignalActive = FMC_WAIT_TIMING_BEFORE_WS;
  hsram1.Init.WriteOperation = FMC_WRITE_OPERATION_ENABLE;
  hsram1.Init.WaitSignal = FMC_WAIT_SIGNAL_DISABLE;
  hsram1.Init.ExtendedMode = FMC_EXTENDED_MODE_DISABLE;
  hsram1.Init.AsynchronousWait = FMC_ASYNCHRONOUS_WAIT_DISABLE;
  hsram1.Init.WriteBurst = FMC_WRITE_BURST_DISABLE;
  hsram1.Init.ContinuousClock = FMC_CONTINUOUS_CLOCK_SYNC_ONLY;
  hsram1.Init.WriteFifo = FMC_WRITE_FIFO_ENABLE;
  hsram1.Init.NBLSetupTime = 0;
  hsram1.Init.PageSize = FMC_PAGE_SIZE_NONE;
  hsram1.Init.MaxChipSelectPulse = DISABLE;
  /* Timing */
  Timing.AddressSetupTime = 0;
  Timing.AddressHoldTime = 15;
  Timing.DataSetupTime = 1;
  Timing.DataHoldTime = 0;
  Timing.BusTurnAroundDuration = 0;
  Timing.CLKDivision = 16;
  Timing.DataLatency = 17;
  Timing.AccessMode = FMC_ACCESS_MODE_A;
  /* ExtTiming */

  if (HAL_SRAM_Init(&hsram1, &Timing, NULL) != HAL_OK)
  {
    Error_Handler( );
  }

}

static void MX_GPIO_Init(void)
{
  LL_GPIO_InitTypeDef GPIO_InitStruct = {0};

  /* GPIO Ports Clock Enable */
  LL_AHB2_GRP1_EnableClock(LL_AHB2_GRP1_PERIPH_GPIOF);
  LL_AHB2_GRP1_EnableClock(LL_AHB2_GRP1_PERIPH_GPIOC);
  LL_AHB2_GRP1_EnableClock(LL_AHB2_GRP1_PERIPH_GPIOA);
  LL_AHB2_GRP1_EnableClock(LL_AHB2_GRP1_PERIPH_GPIOE);
  LL_AHB2_GRP1_EnableClock(LL_AHB2_GRP1_PERIPH_GPIOB);
  LL_AHB2_GRP1_EnableClock(LL_AHB2_GRP1_PERIPH_GPIOD);
  LL_AHB2_GRP1_EnableClock(LL_AHB2_GRP1_PERIPH_GPIOG);

  /**/
  LL_GPIO_ResetOutputPin(LED1_GPIO_Port, LED1_Pin);

  /**/
  LL_GPIO_ResetOutputPin(LED2_GPIO_Port, LED2_Pin);

  /**/
  LL_GPIO_ResetOutputPin(LED3_GPIO_Port, LED3_Pin);

  /**/
  LL_GPIO_ResetOutputPin(LED4_GPIO_Port, LED4_Pin);

  /**/
  LL_GPIO_ResetOutputPin(LED5_GPIO_Port, LED5_Pin);

  /**/
  LL_GPIO_ResetOutputPin(LED6_GPIO_Port, LED6_Pin);

  /**/
  LL_GPIO_ResetOutputPin(LED7_GPIO_Port, LED7_Pin);

  /**/
  LL_GPIO_ResetOutputPin(LED0_GPIO_Port, LED0_Pin);

  /**/
  LL_GPIO_ResetOutputPin(SD_CARD_CS_GPIO_Port, SD_CARD_CS_Pin);

  /**/
  LL_GPIO_ResetOutputPin(LCD_NRST_GPIO_Port, LCD_NRST_Pin);

  /**/
  GPIO_InitStruct.Pin = LED1_Pin;
  GPIO_InitStruct.Mode = LL_GPIO_MODE_OUTPUT;
  GPIO_InitStruct.Speed = LL_GPIO_SPEED_FREQ_LOW;
  GPIO_InitStruct.OutputType = LL_GPIO_OUTPUT_PUSHPULL;
  GPIO_InitStruct.Pull = LL_GPIO_PULL_NO;
  LL_GPIO_Init(LED1_GPIO_Port, &GPIO_InitStruct);

  /**/
  GPIO_InitStruct.Pin = LED2_Pin;
  GPIO_InitStruct.Mode = LL_GPIO_MODE_OUTPUT;
  GPIO_InitStruct.Speed = LL_GPIO_SPEED_FREQ_LOW;
  GPIO_InitStruct.OutputType = LL_GPIO_OUTPUT_PUSHPULL;
  GPIO_InitStruct.Pull = LL_GPIO_PULL_NO;
  LL_GPIO_Init(LED2_GPIO_Port, &GPIO_InitStruct);

  /**/
  GPIO_InitStruct.Pin = LED3_Pin;
  GPIO_InitStruct.Mode = LL_GPIO_MODE_OUTPUT;
  GPIO_InitStruct.Speed = LL_GPIO_SPEED_FREQ_LOW;
  GPIO_InitStruct.OutputType = LL_GPIO_OUTPUT_PUSHPULL;
  GPIO_InitStruct.Pull = LL_GPIO_PULL_NO;
  LL_GPIO_Init(LED3_GPIO_Port, &GPIO_InitStruct);

  /**/
  GPIO_InitStruct.Pin = LED4_Pin;
  GPIO_InitStruct.Mode = LL_GPIO_MODE_OUTPUT;
  GPIO_InitStruct.Speed = LL_GPIO_SPEED_FREQ_LOW;
  GPIO_InitStruct.OutputType = LL_GPIO_OUTPUT_PUSHPULL;
  GPIO_InitStruct.Pull = LL_GPIO_PULL_NO;
  LL_GPIO_Init(LED4_GPIO_Port, &GPIO_InitStruct);

  /**/
  GPIO_InitStruct.Pin = LED5_Pin;
  GPIO_InitStruct.Mode = LL_GPIO_MODE_OUTPUT;
  GPIO_InitStruct.Speed = LL_GPIO_SPEED_FREQ_LOW;
  GPIO_InitStruct.OutputType = LL_GPIO_OUTPUT_PUSHPULL;
  GPIO_InitStruct.Pull = LL_GPIO_PULL_NO;
  LL_GPIO_Init(LED5_GPIO_Port, &GPIO_InitStruct);

  /**/
  GPIO_InitStruct.Pin = LED6_Pin;
  GPIO_InitStruct.Mode = LL_GPIO_MODE_OUTPUT;
  GPIO_InitStruct.Speed = LL_GPIO_SPEED_FREQ_LOW;
  GPIO_InitStruct.OutputType = LL_GPIO_OUTPUT_PUSHPULL;
  GPIO_InitStruct.Pull = LL_GPIO_PULL_NO;
  LL_GPIO_Init(LED6_GPIO_Port, &GPIO_InitStruct);

  /**/
  GPIO_InitStruct.Pin = LED7_Pin;
  GPIO_InitStruct.Mode = LL_GPIO_MODE_OUTPUT;
  GPIO_InitStruct.Speed = LL_GPIO_SPEED_FREQ_LOW;
  GPIO_InitStruct.OutputType = LL_GPIO_OUTPUT_PUSHPULL;
  GPIO_InitStruct.Pull = LL_GPIO_PULL_NO;
  LL_GPIO_Init(LED7_GPIO_Port, &GPIO_InitStruct);

  /**/
  GPIO_InitStruct.Pin = LED0_Pin;
  GPIO_InitStruct.Mode = LL_GPIO_MODE_OUTPUT;
  GPIO_InitStruct.Speed = LL_GPIO_SPEED_FREQ_LOW;
  GPIO_InitStruct.OutputType = LL_GPIO_OUTPUT_PUSHPULL;
  GPIO_InitStruct.Pull = LL_GPIO_PULL_NO;
  LL_GPIO_Init(LED0_GPIO_Port, &GPIO_InitStruct);

  /**/
  GPIO_InitStruct.Pin = SD_CARD_CD_Pin;
  GPIO_InitStruct.Mode = LL_GPIO_MODE_INPUT;
  GPIO_InitStruct.Pull = LL_GPIO_PULL_NO;
  LL_GPIO_Init(SD_CARD_CD_GPIO_Port, &GPIO_InitStruct);

  /**/
  GPIO_InitStruct.Pin = SD_CARD_CS_Pin;
  GPIO_InitStruct.Mode = LL_GPIO_MODE_OUTPUT;
  GPIO_InitStruct.Speed = LL_GPIO_SPEED_FREQ_LOW;
  GPIO_InitStruct.OutputType = LL_GPIO_OUTPUT_PUSHPULL;
  GPIO_InitStruct.Pull = LL_GPIO_PULL_NO;
  LL_GPIO_Init(SD_CARD_CS_GPIO_Port, &GPIO_InitStruct);

  /**/
  GPIO_InitStruct.Pin = BUTTON_UP_Pin;
  GPIO_InitStruct.Mode = LL_GPIO_MODE_INPUT;
  GPIO_InitStruct.Pull = LL_GPIO_PULL_UP;
  LL_GPIO_Init(BUTTON_UP_GPIO_Port, &GPIO_InitStruct);

  /**/
  GPIO_InitStruct.Pin = BUTTON_DOWN_Pin;
  GPIO_InitStruct.Mode = LL_GPIO_MODE_INPUT;
  GPIO_InitStruct.Pull = LL_GPIO_PULL_UP;
  LL_GPIO_Init(BUTTON_DOWN_GPIO_Port, &GPIO_InitStruct);

  /**/
  GPIO_InitStruct.Pin = BUTTON_LEFT_Pin;
  GPIO_InitStruct.Mode = LL_GPIO_MODE_INPUT;
  GPIO_InitStruct.Pull = LL_GPIO_PULL_UP;
  LL_GPIO_Init(BUTTON_LEFT_GPIO_Port, &GPIO_InitStruct);

  /**/
  GPIO_InitStruct.Pin = BUTTON_RIGHT_Pin;
  GPIO_InitStruct.Mode = LL_GPIO_MODE_INPUT;
  GPIO_InitStruct.Pull = LL_GPIO_PULL_UP;
  LL_GPIO_Init(BUTTON_RIGHT_GPIO_Port, &GPIO_InitStruct);

  /**/
  GPIO_InitStruct.Pin = LCD_NRST_Pin;
  GPIO_InitStruct.Mode = LL_GPIO_MODE_OUTPUT;
  GPIO_InitStruct.Speed = LL_GPIO_SPEED_FREQ_LOW;
  GPIO_InitStruct.OutputType = LL_GPIO_OUTPUT_PUSHPULL;
  GPIO_InitStruct.Pull = LL_GPIO_PULL_NO;
  LL_GPIO_Init(LCD_NRST_GPIO_Port, &GPIO_InitStruct);

}

void Error_Handler(void)
{
  __disable_irq();
  while (1)
  {
  }
}
